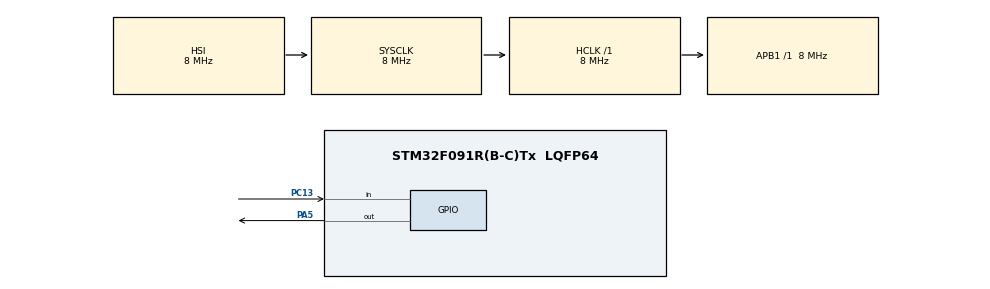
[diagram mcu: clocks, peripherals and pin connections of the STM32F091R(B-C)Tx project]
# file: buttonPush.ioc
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Mcu.Family=STM32F0
Mcu.Name=STM32F091R(B-C)Tx
Mcu.Package=LQFP64
PA5.Signal=GPIO_Output
PC13.Signal=GPIO_Input
ProjectManager.HeapSize=0x200
ProjectManager.StackSize=0x400
ProjectManager.TargetToolchain=SW4STM32
RCC.AHBFreq_Value=8000000
RCC.APB1Freq_Value=8000000
RCC.APB1TimFreq_Value=8000000
RCC.FLatency-AdvancedSettings=FLASH_LATENCY_0
RCC.HCLKFreq_Value=8000000
RCC.PLLDivider=RCC_PREDIV_DIV2
RCC.PLLMUL=RCC_PLL_MUL12
RCC.PREFETCH_ENABLE-AdvancedSettings=1
RCC.SYSCLKFreq_VALUE=8000000
board=NUCLEO-F091RC

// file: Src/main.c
/* USER CODE BEGIN Header */
/**
  ******************************************************************************
  * @file           : main.c
  * @brief          : Main program body
  ******************************************************************************
  * @attention
  *
  * <h2><center>&copy; Copyright (c) 2020 STMicroelectronics.
  * All rights reserved.</center></h2>
  *
  * This software component is licensed by ST under BSD 3-Clause license,
  * the "License"; You may not use this file except in compliance with the
  * License. You may obtain a copy of the License at:
  *                        opensource.org/licenses/BSD-3-Clause
  *
  ******************************************************************************
  */
/* USER CODE END Header */

#include "main.h"

void SystemClock_Config(void);
static void MX_GPIO_Init(void);

int main(void)
{

  /* MCU Configuration--------------------------------------------------------*/

  /* Reset of all peripherals, Initializes the Flash interface and the Systick. */
  HAL_Init();

  /* Configure the system clock */
  SystemClock_Config();

  /* Initialize all configured peripherals */
  MX_GPIO_Init();

  /* Infinite loop */
  while (1)
  {

    /* USER CODE BEGIN 3 */
	  if(HAL_GPIO_ReadPin(GPIOC, GPIO_PIN_13) == GPIO_PIN_SET) //Se botão está pressionado
	  	{
	  		 HAL_GPIO_WritePin(GPIOA, GPIO_PIN_5, GPIO_PIN_RESET); //LED ligado
	  	}
	  else //botão não está pressionado
	  	{
	  		 HAL_GPIO_WritePin(GPIOA, GPIO_PIN_5, GPIO_PIN_SET); //LED desligado
	  	}
  }
  /* USER CODE END 3 */
}

void SystemClock_Config(void)
{
  RCC_OscInitTypeDef RCC_OscInitStruct = {0};
  RCC_ClkInitTypeDef RCC_ClkInitStruct = {0};

  /** Initializes the CPU, AHB and APB busses clocks
  */
  RCC_OscInitStruct.OscillatorType = RCC_OSCILLATORTYPE_HSI;
  RCC_OscInitStruct.HSIState = RCC_HSI_ON;
  RCC_OscInitStruct.HSICalibrationValue = RCC_HSICALIBRATION_DEFAULT;
  RCC_OscInitStruct.PLL.PLLState = RCC_PLL_NONE;
  if (HAL_RCC_OscConfig(&RCC_OscInitStruct) != HAL_OK)
  {
    Error_Handler();
  }
  /** Initializes the CPU, AHB and APB busses clocks
  */
  RCC_ClkInitStruct.ClockType = RCC_CLOCKTYPE_HCLK|RCC_CLOCKTYPE_SYSCLK
                              |RCC_CLOCKTYPE_PCLK1;
  RCC_ClkInitStruct.SYSCLKSource = RCC_SYSCLKSOURCE_HSI;
  RCC_ClkInitStruct.AHBCLKDivider = RCC_SYSCLK_DIV1;
  RCC_ClkInitStruct.APB1CLKDivider = RCC_HCLK_DIV1;

  if (HAL_RCC_ClockConfig(&RCC_ClkInitStruct, FLASH_LATENCY_0) != HAL_OK)
  {
    Error_Handler();
  }
}

static void MX_GPIO_Init(void)
{
  GPIO_InitTypeDef GPIO_InitStruct = {0};

  /* GPIO Ports Clock Enable */
  __HAL_RCC_GPIOC_CLK_ENABLE();
  __HAL_RCC_GPIOA_CLK_ENABLE();

  /*Configure GPIO pin Output Level */
  HAL_GPIO_WritePin(GPIOA, GPIO_PIN_5, GPIO_PIN_RESET);

  /*Configure GPIO pin : PC13 */
  GPIO_InitStruct.Pin = GPIO_PIN_13;
  GPIO_InitStruct.Mode = GPIO_MODE_INPUT;
  GPIO_InitStruct.Pull = GPIO_NOPULL;
  HAL_GPIO_Init(GPIOC, &GPIO_InitStruct);

  /*Configure GPIO pin : PA5 */
  GPIO_InitStruct.Pin = GPIO_PIN_5;
  GPIO_InitStruct.Mode = GPIO_MODE_OUTPUT_PP;
  GPIO_InitStruct.Pull = GPIO_NOPULL;
  GPIO_InitStruct.Speed = GPIO_SPEED_FREQ_LOW;
  HAL_GPIO_Init(GPIOA, &GPIO_InitStruct);

}

void Error_Handler(void)
{
}

/************************ (C) COPYRIGHT STMicroelectronics *****END OF FILE****/
